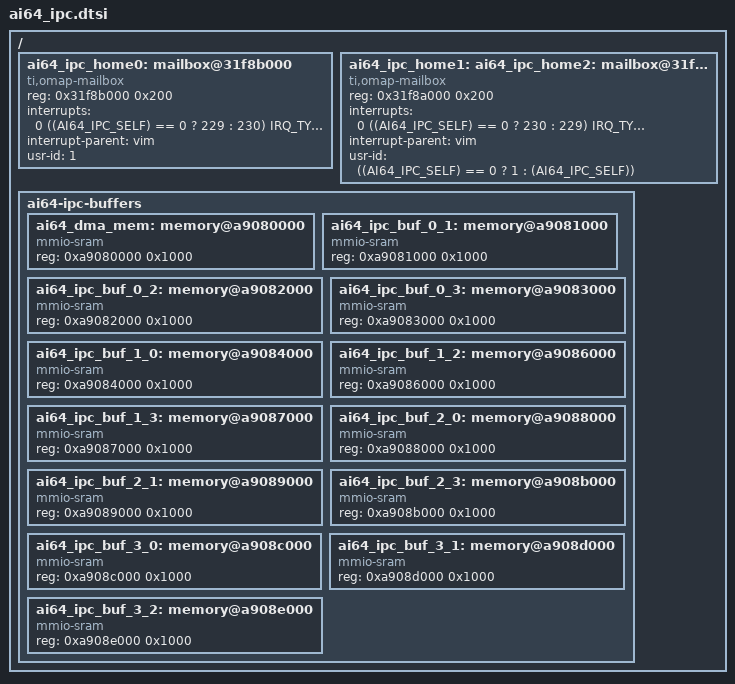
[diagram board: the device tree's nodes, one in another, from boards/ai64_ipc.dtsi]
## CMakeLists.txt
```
cmake_minimum_required(VERSION 3.20.0)

find_package(Zephyr REQUIRED HINTS $ENV{ZEPHYR_BASE})

project(ai64_r5 C CXX)

# EmbeddedRPC 1.14.0, cloned by build.sh. It is not used as a Zephyr module:
# that module's Kconfig selects SERIAL from a symbol that depends on the full
# C++ library, and the loop fails configuration. The library sources are
# compiled here, with erpc_malloc/erpc_free on the Zephyr heap. Transport is
# the existing OpenAMP RPMsg endpoint, not the module's UART or RPMsg-Lite
# ports.
set(ERPC ${CMAKE_CURRENT_LIST_DIR}/../../third_party/erpc/erpc_c)

# "r5f0_0" for board beaglebone_ai64/j721e/main_r5f0_0. The code names its
# core in logs with it, and in replies with AI64_CORE_NAME, "R5F0_0".
string(REGEX MATCH "r5f[0-9]_[0-9]" AI64_CORE "${BOARD_QUALIFIERS}")
if(NOT AI64_CORE)
  message(FATAL_ERROR "zephyr/r5 builds for a main-domain R5F core, not ${BOARD}${BOARD_QUALIFIERS}")
endif()
string(TOUPPER "${AI64_CORE}" AI64_CORE_NAME)
target_compile_definitions(app PRIVATE AI64_CORE="${AI64_CORE}" AI64_CORE_NAME="${AI64_CORE_NAME}")

# Its number among the four R5F cores (src/ai64_ipc.h), and its node on the
# fabric (zephyr/include/ai64_fabric.h), one more.
set(AI64_SELF_r5f0_0 0)
set(AI64_SELF_r5f0_1 1)
set(AI64_SELF_r5f1_0 2)
set(AI64_SELF_r5f1_1 3)
math(EXPR AI64_FAB_NODE "${AI64_SELF_${AI64_CORE}} + 1")
target_compile_definitions(app PRIVATE AI64_SELF=${AI64_SELF_${AI64_CORE}} AI64_FAB_NODE=${AI64_FAB_NODE})

target_include_directories(app PRIVATE
  ${CMAKE_CURRENT_SOURCE_DIR}/../include
  ${CMAKE_CURRENT_SOURCE_DIR}/../../dsp/include
  ${CMAKE_CURRENT_SOURCE_DIR}/../erpc/shim
  ${CMAKE_CURRENT_SOURCE_DIR}/src
  ${ERPC}/infra
  ${ERPC}/port
  ${ERPC}/setup
  ${LIBMETAL_INCLUDE_DIR}
  ${OPENAMP_INCLUDE_DIR}
  ${PLATFORM_DIR}
)

target_sources(app PRIVATE
  src/main.c
  src/ai64_service.c
  src/ai64_restart.c
  src/ai64_mpu.c
  src/ai64_tisci.c
  src/ai64_sproxy.c
  src/ai64_fabric.c
  src/ai64_ipc.c
  src/ai64_jobs.c
  src/ai64_erpc.cpp
  src/erpc_port_zephyr.cpp
  ../erpc/shim/c_ai64_server.cpp
  ../erpc/shim/ai64_server.cpp
  ../erpc/shim/ai64_interface.cpp
  ${ERPC}/infra/erpc_basic_codec.cpp
  ${ERPC}/infra/erpc_crc16.cpp
  ${ERPC}/infra/erpc_framed_transport.cpp
  ${ERPC}/infra/erpc_message_buffer.cpp
  ${ERPC}/infra/erpc_message_loggers.cpp
  ${ERPC}/infra/erpc_pre_post_action.cpp
  ${ERPC}/infra/erpc_server.cpp
  ${ERPC}/infra/erpc_simple_server.cpp
  ${ERPC}/infra/erpc_utils.cpp
  ${ERPC}/setup/erpc_server_setup.cpp
  ${ERPC}/setup/erpc_setup_mbf_dynamic.cpp
)

# This core's job (Kconfig, set in boards/<board>.conf).
target_sources_ifdef(CONFIG_AI64_JOB_SPI     app PRIVATE src/ai64_spi.c)
target_sources_ifdef(CONFIG_AI64_JOB_PWM     app PRIVATE src/ai64_pwm.c)
target_sources_ifdef(CONFIG_AI64_JOB_BLINK   app PRIVATE src/ai64_blink.c)
target_sources_ifdef(CONFIG_AI64_JOB_MONITOR app PRIVATE src/ai64_monitor.c)
target_sources_ifdef(CONFIG_AI64_DMA         app PRIVATE src/ai64_dma.c)
if(CONFIG_AI64_PIPE)
  target_sources_ifdef(CONFIG_AI64_JOB_SPI   app PRIVATE src/ai64_pipe_dma.c)
  target_sources_ifdef(CONFIG_AI64_JOB_PWM   app PRIVATE src/ai64_pipe_pwm.c)
endif()
```

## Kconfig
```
# SPDX-License-Identifier: MIT
#
# One app for the four main-domain R5F cores. sysbuild.cmake builds it once
# per core, and each core's boards/<board>.conf picks its job here. Every
# core also answers Linux over eRPC, sits on the fabric, and links to the
# other three over ipc_service (src/ai64_ipc.c).

menu "BeagleBone AI-64 demo"

choice AI64_JOB
	prompt "This core's job"

config AI64_JOB_SPI
	bool "SPI7 on header P9, and the UART2 console"
	help
	  R5F0_0. Writes SPI7 for Linux and for the other cores, and holds
	  the bulk buffer Linux writes.

config AI64_JOB_PWM
	bool "EHRPWM4 on P9.25"
	help
	  R5F0_1. Runs the step program on P9.25 and takes fixed settings
	  from Linux, the other cores, and fabric routes.

config AI64_JOB_BLINK
	bool "A square wave on P8.18 from a kernel timer"
	help
	  R5F1_0. Toggles GPIO0_4 from a k_timer and measures how late each
	  toggle is, on the GTC.

config AI64_JOB_MONITOR
	bool "Pings the other three cores and collects their status"
	help
	  R5F1_1. Measures each link's round trip and gathers every core's
	  job status for Linux.

endchoice

config AI64_DMA
	bool "A UDMA memory-to-memory channel (src/ai64_dma.c)"
	default y if AI64_JOB_SPI
	help
	  R5F0_0. Copies between DDR and the DSPs' memories for Linux's
	  dmaCopy call, with the main NAVSS UDMA.

config AI64_PIPE
	bool "This core's stage of the pipeline (zephyr/include/ai64_pipe.h)"
	default y if AI64_JOB_SPI || AI64_JOB_PWM
	select AI64_DMA if AI64_JOB_SPI
	help
	  R5F0_0 copies each window of P8.31 samples from ICSSG0 into C66x
	  0's L2 SRAM with its UDMA (src/ai64_pipe_dma.c). R5F0_1 sets P9.25
	  from the class the C7x finds for it, and keeps score
	  (src/ai64_pipe_pwm.c).

config AI64_BLINK_HALF_PERIOD_US
	int "Half period of the P8.18 square wave, in microseconds"
	depends on AI64_JOB_BLINK
	default 500

config AI64_MONITOR_PERIOD_MS
	int "How often the monitor pings every core, in milliseconds"
	depends on AI64_JOB_MONITOR
	default 100

endmenu

source "Kconfig.zephyr"
```

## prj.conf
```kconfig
CONFIG_IPM=y
CONFIG_MBOX=y
CONFIG_CPP=y
CONFIG_STD_CPP17=y
CONFIG_REQUIRES_FULL_LIBCPP=y
CONFIG_GLIBCXX_LIBCPP=y
CONFIG_MAIN_STACK_SIZE=2048
CONFIG_HEAP_MEM_POOL_SIZE=8192
CONFIG_SYSTEM_WORKQUEUE_STACK_SIZE=2048
CONFIG_OPENAMP=y
CONFIG_OPENAMP_RSC_TABLE=y
CONFIG_OPENAMP_MASTER=n
CONFIG_OPENAMP_RSC_TABLE_NUM_RPMSG_BUFF=8
CONFIG_LOG=y
CONFIG_LOG_DEFAULT_LEVEL=3
CONFIG_CACHE_MANAGEMENT=y
# TI-SCI over the polled secure proxy (src/ai64_sproxy.c), which starts at
# PRE_KERNEL_1 priority 5. Power domains, on R5F0_1 and R5F1_0, come after it.
CONFIG_TISCI_INIT_PRIORITY=10
# The links to the other R5F cores (src/ai64_ipc.c): ipc_service on the
# icmsg backend. A message is up to 180 bytes, more than pbuf's default
# read buffer.
CONFIG_IPC_SERVICE=y
CONFIG_PBUF_RX_READ_BUF_SIZE=256
```

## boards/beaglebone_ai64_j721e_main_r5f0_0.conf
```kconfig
# The ELF is build/zephyr-main_r5f0_0/zephyr/ai64_r5f0_0.elf. That is not the
# kernel's default name (j7-main-r5f0_0-fw), so the core stays off at boot
# until ai64-demo starts it.
CONFIG_KERNEL_BIN_NAME="ai64_r5f0_0"

# This core's job: SPI7 on header P9 (src/ai64_spi.c). It keeps the board's
# UART2 console.
CONFIG_AI64_JOB_SPI=y
CONFIG_SPI=y
```

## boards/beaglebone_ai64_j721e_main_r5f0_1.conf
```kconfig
# The ELF is build/zephyr-main_r5f0_1/zephyr/ai64_r5f0_1.elf. That is not the
# kernel's default name (j7-main-r5f0_1-fw), so the core stays off at boot
# until ai64-demo starts it.
CONFIG_KERNEL_BIN_NAME="ai64_r5f0_1"

# This core's job: EHRPWM4 on P9.25 (src/ai64_pwm.c). The device manager
# gives it its clock and power, over TI-SCI; the power domain turns it on at
# boot.
CONFIG_AI64_JOB_PWM=y
CONFIG_PWM=y
CONFIG_CLOCK_CONTROL=y
CONFIG_POWER_DOMAIN=y
CONFIG_POWER_DOMAIN_TISCI_INIT_PRIORITY=20

# This core has no console UART. Its log goes to a RAM buffer that the
# resource table lists as a trace, so Linux reads it at
# /sys/kernel/debug/remoteproc/remoteprocN/trace0.
CONFIG_CONSOLE=y
CONFIG_RAM_CONSOLE=y
CONFIG_LOG_MODE_MINIMAL=y
```

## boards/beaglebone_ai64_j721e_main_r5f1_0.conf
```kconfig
# The ELF is build/zephyr-main_r5f1_0/zephyr/ai64_r5f1_0.elf. That is not the
# kernel's default name (j7-main-r5f1_0-fw), so the core stays off at boot
# until ai64-demo starts it.
CONFIG_KERNEL_BIN_NAME="ai64_r5f1_0"

# This core's job: a square wave on P8.18 from GPIO2 (src/ai64_blink.c).
# The device manager powers GPIO2, over TI-SCI; the power domain turns it on
# at boot, before the GPIO driver starts.
CONFIG_AI64_JOB_BLINK=y
CONFIG_GPIO=y
CONFIG_POWER_DOMAIN=y
CONFIG_POWER_DOMAIN_TISCI_INIT_PRIORITY=20

# This core has no console UART. Its log goes to a RAM buffer that the
# resource table lists as a trace, so Linux reads it at
# /sys/kernel/debug/remoteproc/remoteprocN/trace0.
CONFIG_CONSOLE=y
CONFIG_RAM_CONSOLE=y
CONFIG_LOG_MODE_MINIMAL=y
```

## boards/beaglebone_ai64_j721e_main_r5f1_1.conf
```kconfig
# The ELF is build/zephyr-main_r5f1_1/zephyr/ai64_r5f1_1.elf. That is not the
# kernel's default name (j7-main-r5f1_1-fw), so the core stays off at boot
# until ai64-demo starts it.
CONFIG_KERNEL_BIN_NAME="ai64_r5f1_1"

# This core's job: ping the other three cores and collect their status
# (src/ai64_monitor.c).
CONFIG_AI64_JOB_MONITOR=y

# This core has no console UART. Its log goes to a RAM buffer that the
# resource table lists as a trace, so Linux reads it at
# /sys/kernel/debug/remoteproc/remoteprocN/trace0.
CONFIG_CONSOLE=y
CONFIG_RAM_CONSOLE=y
CONFIG_LOG_MODE_MINIMAL=y
```

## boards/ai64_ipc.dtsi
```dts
// SPDX-License-Identifier: MIT
/*
 * The R5F cores' links to each other: Zephyr ipc_service, icmsg backend.
 *
 * Every core has a link to every other, twelve one-way buffers in all. Core
 * n is R5F0_0, R5F0_1, R5F1_0, R5F1_1 for n = 0 to 3. The buffer from core
 * a to core b is 4 KiB at 0xa9080000 + (4a + b) * 4 KiB, inside the 1 MiB
 * the Linux overlay reserves for the fabric (which uses the first 128 KiB).
 *
 * Its doorbell is a FIFO of core b's home mailbox. Only two NAVSS mailbox
 * clusters have nobody listening after boot: 10 and 11 (the MCU R5F's
 * firmware, which runs the device manager, listens on cluster 7, and posts
 * to 5, 6, 8, and 9). Only users 1 to 3 of a cluster reach the interrupt
 * router. So cores 1 to 3 are users 1 to 3 of cluster 10, on FIFO 4a + b;
 * core 0 is user 1 of cluster 11, on FIFO 11 + a, since the fabric uses
 * that cluster's FIFOs 0 to 9 (ai64_fabric.h), without interrupts. Each core
 * asks the device manager to route its user's interrupt to its VIM input
 * 229 (src/ai64_tisci.c). A core sends on the other cluster too, but takes
 * no interrupt from it.
 *
 * A board overlay defines AI64_IPC_SELF, includes this file, and adds one
 * AI64_IPC_LINK(self, peer) for each of the other three cores.
 *
 * The slot for core 0 to itself carries no link: R5F0_0 keeps its DMA
 * rings and descriptor there (src/ai64_dma.c), non-cacheable like the rest.
 */

/*
 * unbound = "enable": a core that restarts opens its links with a new
 * session number, and the peer gets an unbound callback and opens the link
 * again (src/ai64_ipc.c). The buffers are non-cacheable on every core
 * (src/ai64_mpu.c); dcache-alignment keeps pbuf's indexes on their own
 * 32-byte lines anyway, which the session handshake needs.
 */
#define AI64_IPC_FIFO(a, b) ((b) == 0 ? 11 + (a) : (a) * 4 + (b))

#define AI64_IPC_LINK(self, peer)                                              \
	ai64_ipc_peer##peer: ipc_peer##peer {                                  \
		compatible = "zephyr,ipc-icmsg";                               \
		tx-region = <&ai64_ipc_buf_##self##_##peer>;                   \
		rx-region = <&ai64_ipc_buf_##peer##_##self>;                   \
		mboxes = <&ai64_ipc_home##peer AI64_IPC_FIFO(self, peer)>,     \
			 <&ai64_ipc_home##self AI64_IPC_FIFO(peer, self)>;     \
		mbox-names = "tx", "rx";                                       \
		unbound = "enable";                                            \
		dcache-alignment = <32>;                                       \
		status = "okay";                                               \
	};

/*
 * The cluster this core does not take interrupts from still needs one in
 * its node; VIM 230 is never routed or enabled.
 */
/ {
	ai64_ipc_home0: mailbox@31f8b000 {
		compatible = "ti,omap-mailbox";
		reg = <0x31f8b000 0x200>;
		interrupts = <0 ((AI64_IPC_SELF) == 0 ? 229 : 230) IRQ_TYPE_LEVEL
			      IRQ_DEFAULT_PRIORITY>;
		interrupt-parent = <&vim>;
		usr-id = <1>;
		#mbox-cells = <1>;
	};

	ai64_ipc_home1: ai64_ipc_home2: ai64_ipc_home3: mailbox@31f8a000 {
		compatible = "ti,omap-mailbox";
		reg = <0x31f8a000 0x200>;
		interrupts = <0 ((AI64_IPC_SELF) == 0 ? 230 : 229) IRQ_TYPE_LEVEL
			      IRQ_DEFAULT_PRIORITY>;
		interrupt-parent = <&vim>;
		usr-id = <((AI64_IPC_SELF) == 0 ? 1 : (AI64_IPC_SELF))>;
		#mbox-cells = <1>;
	};

	ai64-ipc-buffers {
		#address-cells = <1>;
		#size-cells = <1>;
		ranges;
		ai64_dma_mem: memory@a9080000 {
			compatible = "mmio-sram";
			reg = <0xa9080000 0x1000>;
		};
		ai64_ipc_buf_0_1: memory@a9081000 {
			compatible = "mmio-sram";
			reg = <0xa9081000 0x1000>;
		};
		ai64_ipc_buf_0_2: memory@a9082000 {
			compatible = "mmio-sram";
			reg = <0xa9082000 0x1000>;
		};
		ai64_ipc_buf_0_3: memory@a9083000 {
			compatible = "mmio-sram";
			reg = <0xa9083000 0x1000>;
		};
		ai64_ipc_buf_1_0: memory@a9084000 {
			compatible = "mmio-sram";
			reg = <0xa9084000 0x1000>;
		};
		ai64_ipc_buf_1_2: memory@a9086000 {
			compatible = "mmio-sram";
			reg = <0xa9086000 0x1000>;
		};
		ai64_ipc_buf_1_3: memory@a9087000 {
			compatible = "mmio-sram";
			reg = <0xa9087000 0x1000>;
		};
		ai64_ipc_buf_2_0: memory@a9088000 {
			compatible = "mmio-sram";
			reg = <0xa9088000 0x1000>;
		};
		ai64_ipc_buf_2_1: memory@a9089000 {
			compatible = "mmio-sram";
			reg = <0xa9089000 0x1000>;
		};
		ai64_ipc_buf_2_3: memory@a908b000 {
			compatible = "mmio-sram";
			reg = <0xa908b000 0x1000>;
		};
		ai64_ipc_buf_3_0: memory@a908c000 {
			compatible = "mmio-sram";
			reg = <0xa908c000 0x1000>;
		};
		ai64_ipc_buf_3_1: memory@a908d000 {
			compatible = "mmio-sram";
			reg = <0xa908d000 0x1000>;
		};
		ai64_ipc_buf_3_2: memory@a908e000 {
			compatible = "mmio-sram";
			reg = <0xa908e000 0x1000>;
		};
	};
};
```

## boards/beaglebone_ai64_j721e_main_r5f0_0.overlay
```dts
// SPDX-License-Identifier: MIT
#include <zephyr/dt-bindings/pinctrl/ti-k3-pinctrl.h>
#include <freq.h>
#include <zephyr/dt-bindings/interrupt-controller/ti-vim.h>

/*
 * Carve the bulk chunk region out of R5F0_0 DDR: 64 KiB at 0xa2fef000,
 * matching AI64_BULK_ADDR. ddr1 starts at 0xa2200000; the board's ddr1
 * (14 MiB) ended at 0xa3000000, and the last 4 KiB stay unused.
 */

&ddr1 {
	reg = <0xa2200000 0xdef000>;
};

/*
 * 0x200000 is the pad's TX-disable bit (PIN_DISABLE in the Linux header),
 * OR mux mode 7, so a shorted partner ball stays off. The K3 pinctrl helper
 * applies only the first two pinmux cells of each group, so each group has
 * one pin.
 */
#define AI64_PIN_OFF 0x200000

/ {
	ai64_bulk: memory@a2fef000 {
		compatible = "zephyr,memory-region", "mmio-sram";
		reg = <0xa2fef000 0x10000>;
		zephyr,memory-region = "AI64_BULK";
	};

	/*
	 * Main SPI7. Linux leaves it disabled, and the board firmware keeps
	 * its power domain on. The driver polls, so there is no interrupt.
	 * Its functional clock is 50 MHz: with 48 here, the driver's divider
	 * of 48 for 1 MHz gave a 0.96 us clock on a logic analyzer.
	 */
	main_spi7: spi@2170000 {
		compatible = "ti,omap-mcspi";
		reg = <0x02170000 0x400>;
		clock-frequency = <DT_FREQ_M(50)>;
		ti,spi-num-cs = <1>;
		ti,d1-miso-d0-mosi;
		#address-cells = <1>;
		#size-cells = <0>;
		pinctrl-names = "default";
		pinctrl-0 = <&ai64_spi7_clk &ai64_spi7_cs0 &ai64_spi7_d0
			     &ai64_spi7_off_p9_31b &ai64_spi7_off_p9_28b
			     &ai64_spi7_off_p9_30b>;
		status = "okay";
	};
};

&pinctrl {
	ai64_spi7_clk: ai64-spi7-clk {
		/* P9.31a U3 EXT_REFCLK1.SPI7_CLK, mode 6 */
		pinmux = <K3_PINMUX(0x0234, PIN_OUTPUT, MUX_MODE_6)>;
	};
	ai64_spi7_cs0: ai64-spi7-cs0 {
		/* P9.28a U2 ECAP0_IN_APWM_OUT.SPI7_CS0, mode 6 */
		pinmux = <K3_PINMUX(0x0230, PIN_OUTPUT, MUX_MODE_6)>;
	};
	ai64_spi7_d0: ai64-spi7-d0 {
		/* P9.30a V6 TIMER_IO0.SPI7_D0, MOSI, mode 6 */
		pinmux = <K3_PINMUX(0x0238, PIN_OUTPUT, MUX_MODE_6)>;
	};
	ai64_spi7_off_p9_31b: ai64-spi7-off-p9-31b {
		/* P9.31b AB26, shorted to P9.31a */
		pinmux = <K3_PINMUX(0x00d4, AI64_PIN_OFF, MUX_MODE_7)>;
	};
	ai64_spi7_off_p9_28b: ai64-spi7-off-p9-28b {
		/* P9.28b AF28, shorted to P9.28a */
		pinmux = <K3_PINMUX(0x00b0, AI64_PIN_OFF, MUX_MODE_7)>;
	};
	ai64_spi7_off_p9_30b: ai64-spi7-off-p9-30b {
		/* P9.30b AE28, shorted to P9.30a */
		pinmux = <K3_PINMUX(0x00b4, AI64_PIN_OFF, MUX_MODE_7)>;
	};
};

/*
 * TI-SCI, the device manager's API. Zephyr's TI-SCI driver talks to it over
 * this host's (35) threads on main_sec_proxy0: 63 (low_priority,
 * write) and 61 (response, read; k3conf show threads). The polled mailbox
 * driver in src/ai64_sproxy.c carries it, since no secure proxy interrupt
 * reaches an R5F here. reg is the device manager's debug window, which the
 * binding asks for and nothing reads.
 */
/ {
	ai64_sproxy: mailbox@32c00000 {
		compatible = "ai64,secure-proxy-poll";
		reg = <0x32c00000 0x100000>, <0x32400000 0x100000>;
		reg-names = "target_data", "rt";
		#mbox-cells = <1>;
	};

	dmsc: system-controller@44083000 {
		compatible = "ti,k2g-sci";
		reg = <0x44083000 0x1000>;
		ti,host-id = <35>;
		mboxes = <&ai64_sproxy 61>, <&ai64_sproxy 63>;
		mbox-names = "rx", "tx";
	};
};

/*
 * The mailbox interrupt route this core asks the device manager for at boot
 * (src/ai64_tisci.c), through Zephyr's TI-SCI driver.
 * NAVSS0_MAILBOX_1 user 2 arrives on NAVSS0_INTR_ROUTER_0
 * (device 213) input 434. Output 196 is the first of this host's range
 * (k3conf dump rm 213) and lands on this core's VIM input 228.
 */
/ {
	ai64_tisci: tisci-route {
		compatible = "ai64,tisci-irq-route";
		ir-id = <213>;
		ir-input = <434>;
		ir-output = <196>;
	};
};

/* The board puts the mailbox on VIM 256, which nothing routes to. */
&mbox1 {
	interrupts = <0 228 IRQ_TYPE_LEVEL IRQ_DEFAULT_PRIORITY>;
};

/*
 * The links to the other three R5F cores (boards/ai64_ipc.dtsi). This core's
 * doorbells are NAVSS0_MAILBOX_11 user 1, which arrives on router input 393
 * (TI-SCI's pend_intr 0); output 197, the next of this host's range, lands
 * on VIM input 229.
 */
#define AI64_IPC_SELF 0
#include "ai64_ipc.dtsi"

/ {
	ai64_tisci_ipc: tisci-route-ipc {
		compatible = "ai64,tisci-irq-route";
		ir-id = <213>;
		ir-input = <393>;
		ir-output = <197>;
	};

	AI64_IPC_LINK(0, 1)
	AI64_IPC_LINK(0, 2)
	AI64_IPC_LINK(0, 3)
};
```

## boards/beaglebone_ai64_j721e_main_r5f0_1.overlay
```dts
// SPDX-License-Identifier: MIT
#include <zephyr/dt-bindings/pinctrl/ti-k3-pinctrl.h>
#include <zephyr/dt-bindings/interrupt-controller/ti-vim.h>
#include <zephyr/dt-bindings/pwm/pwm.h>

/*
 * R5F0_1's job: EHRPWM4 output B on P9.25 (src/ai64_pwm.c).
 *
 * 0x200000 is the pad's TX-disable bit (PIN_DISABLE in the Linux header),
 * OR mux mode 7, so the shorted partner ball stays off. The K3 pinctrl
 * helper applies only the first two pinmux cells of each group, so each
 * group has one pin.
 */
#define AI64_PIN_OFF 0x200000

&pinctrl {
	ai64_epwm4_b: ai64-epwm4-b {
		/* P9.25b W26 RGMII6_RXC.EHRPWM4_B, mode 6 */
		pinmux = <K3_PINMUX(0x01a4, PIN_OUTPUT, MUX_MODE_6)>;
	};
	ai64_epwm4_off_p9_25a: ai64-epwm4-off-p9-25a {
		/* P9.25a AC4, shorted to P9.25b */
		pinmux = <K3_PINMUX(0x0200, AI64_PIN_OFF, MUX_MODE_7)>;
	};
};

/*
 * Zephyr's EHRPWM driver (ti,am3352-ehrpwm). Its functional clock and power
 * come from the device manager over TI-SCI (dmsc, below): device 87, clock
 * 0, as in the Linux device tree's main_ehrpwm4. The power domain turns the
 * module on at boot. The time-base clock gate is CTRLMMR_EPWM4_CTRL bit 0,
 * at 0x4150 in CTRL_MMR0 (Linux's ehrpwm_tbclk 4), in the partition that
 * kicks at 0x5008. Linux leaves EHRPWM4 alone once install-beagle.sh has
 * taken the stock image's epwm4 overlay out of its boot entry.
 * src/ai64_pwm.c drives it, through the pwms of /zephyr,user.
 */
/ {
	main_ctrl_mmr0: syscon@100000 {
		compatible = "ti,control-module", "syscon";
		reg = <0x00100000 0x1c000>;
		ti,unlock-offsets = <0x5008>;
		#epwm-tbclk-cells = <2>;
	};

	power-domains {
		epwm4_pd: epwm4-pd {
			compatible = "ti,sci-pm-domain";
			tisci,device-id = <87>;
			tisci,device-mode = "EXCLUSIVE";
			#power-domain-cells = <0>;
		};
	};

	main_ehrpwm4: pwm@3040000 {
		compatible = "ti,am3352-ehrpwm";
		reg = <0x03040000 0x100>;
		clocks = <&k3_clks 87 0>;
		tbclk = <&main_ctrl_mmr0 0x4150 0>;
		power-domains = <&epwm4_pd>;
		pinctrl-0 = <&ai64_epwm4_b &ai64_epwm4_off_p9_25a>;
		pinctrl-names = "default";
		#pwm-cells = <3>;
	};

	zephyr,user {
		/* Output B is channel 1. 1 kHz until the steps start. */
		pwms = <&main_ehrpwm4 1 PWM_MSEC(1) PWM_POLARITY_NORMAL>;
	};
};

/*
 * TI-SCI, the device manager's API. Zephyr's TI-SCI driver talks to it over
 * this host's (37) threads on main_sec_proxy0: 73 (low_priority,
 * write) and 71 (response, read; k3conf show threads). The polled mailbox
 * driver in src/ai64_sproxy.c carries it, since no secure proxy interrupt
 * reaches an R5F here. reg is the device manager's debug window, which the
 * binding asks for and nothing reads.
 */
/ {
	ai64_sproxy: mailbox@32c00000 {
		compatible = "ai64,secure-proxy-poll";
		reg = <0x32c00000 0x100000>, <0x32400000 0x100000>;
		reg-names = "target_data", "rt";
		#mbox-cells = <1>;
	};

	dmsc: system-controller@44083000 {
		compatible = "ti,k2g-sci";
		reg = <0x44083000 0x1000>;
		ti,host-id = <37>;
		mboxes = <&ai64_sproxy 71>, <&ai64_sproxy 73>;
		mbox-names = "rx", "tx";

		k3_clks: clock-controller {
			compatible = "ti,k2g-sci-clk";
			#clock-cells = <2>;
		};
	};
};

/*
 * The mailbox interrupt routes this core asks the device manager for at
 * boot (src/ai64_tisci.c), through Zephyr's TI-SCI driver, both on
 * NAVSS0_INTR_ROUTER_0 (device 213), whose outputs 228 to 255 are this
 * host's (k3conf dump rm 213) and land on this core's VIM inputs 228 to 255:
 * - Linux's doorbell, NAVSS0_MAILBOX_1 user 1: router input 433, output 228,
 *   VIM 228.
 * - The other R5F cores' doorbells, NAVSS0_MAILBOX_10 user 1
 *   (boards/ai64_ipc.dtsi): router input 397 (TI-SCI's pend_intr 0),
 *   output 229, VIM 229.
 */
/ {
	ai64_tisci: tisci-route {
		compatible = "ai64,tisci-irq-route";
		ir-id = <213>;
		ir-input = <433>;
		ir-output = <228>;
	};

	ai64_tisci_ipc: tisci-route-ipc {
		compatible = "ai64,tisci-irq-route";
		ir-id = <213>;
		ir-input = <397>;
		ir-output = <229>;
	};
};

/* The board puts the mailbox on VIM 256, which nothing routes to. */
&mbox1 {
	interrupts = <0 228 IRQ_TYPE_LEVEL IRQ_DEFAULT_PRIORITY>;
};

#define AI64_IPC_SELF 1
#include "ai64_ipc.dtsi"

/ {
	AI64_IPC_LINK(1, 0)
	AI64_IPC_LINK(1, 2)
	AI64_IPC_LINK(1, 3)
};
```

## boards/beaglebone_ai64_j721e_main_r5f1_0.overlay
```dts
// SPDX-License-Identifier: MIT
#include <zephyr/dt-bindings/interrupt-controller/ti-vim.h>

/*
 * TI-SCI, the device manager's API. Zephyr's TI-SCI driver talks to it over
 * this host's (40) threads on main_sec_proxy0: 83 (low_priority,
 * write) and 81 (response, read; k3conf show threads). The polled mailbox
 * driver in src/ai64_sproxy.c carries it, since no secure proxy interrupt
 * reaches an R5F here. reg is the device manager's debug window, which the
 * binding asks for and nothing reads.
 */
/ {
	ai64_sproxy: mailbox@32c00000 {
		compatible = "ai64,secure-proxy-poll";
		reg = <0x32c00000 0x100000>, <0x32400000 0x100000>;
		reg-names = "target_data", "rt";
		#mbox-cells = <1>;
	};

	dmsc: system-controller@44083000 {
		compatible = "ti,k2g-sci";
		reg = <0x44083000 0x1000>;
		ti,host-id = <40>;
		mboxes = <&ai64_sproxy 81>, <&ai64_sproxy 83>;
		mbox-names = "rx", "tx";
	};
};

/*
 * The mailbox interrupt route this core asks the device manager for at boot
 * (src/ai64_tisci.c), through Zephyr's TI-SCI driver.
 * NAVSS0_MAILBOX_2 user 1 arrives on NAVSS0_INTR_ROUTER_0
 * (device 213) input 429. Output 260 is the first of this host's range
 * (k3conf dump rm 213) and lands on this core's VIM input 228.
 */
/ {
	ai64_tisci: tisci-route {
		compatible = "ai64,tisci-irq-route";
		ir-id = <213>;
		ir-input = <429>;
		ir-output = <260>;
	};
};

/* The board puts the mailbox on VIM 256, which nothing routes to. */
&mbox2 {
	interrupts = <0 228 IRQ_TYPE_LEVEL IRQ_DEFAULT_PRIORITY>;
};

/*
 * The links to the other three R5F cores (boards/ai64_ipc.dtsi). This core's
 * doorbells are NAVSS0_MAILBOX_10 user 2, which arrives on router input
 * 398 (TI-SCI's pend_intr 1); output 261, the next of this host's range,
 * lands on VIM input 229.
 */
#define AI64_IPC_SELF 2
#include "ai64_ipc.dtsi"

/ {
	ai64_tisci_ipc: tisci-route-ipc {
		compatible = "ai64,tisci-irq-route";
		ir-id = <213>;
		ir-input = <398>;
		ir-output = <261>;
	};

	AI64_IPC_LINK(2, 0)
	AI64_IPC_LINK(2, 1)
	AI64_IPC_LINK(2, 3)
};

/*
 * R5F1_0's job: a square wave on P8.18 (src/ai64_blink.c).
 *
 * The pad, AJ23 at 0x010, is GPIO0_4 in mux mode 7. Bits 5:4 of a J721E
 * pad register pick which of the main domain's GPIO0, GPIO2, GPIO4, and
 * GPIO6 drives it (1 is GPIO2). Linux owns GPIO0, and has outputs in every
 * one of its banks, but leaves GPIO2 disabled, so this core takes GPIO2
 * whole: Zephyr's GPIO driver sets every pin of a bank to input when it
 * starts. GPIO2's power and clock come from the device manager (device
 * 107), which the power domain turns on at boot.
 */
#include <zephyr/dt-bindings/pinctrl/ti-k3-pinctrl.h>
#include <zephyr/dt-bindings/gpio/gpio.h>

#define AI64_GPIO2_SEL (1 << 4)

&pinctrl {
	ai64_blink_p8_18: ai64-blink-p8-18 {
		/* P8.18 AJ23 GPIO0_4, here GPIO2_4, mode 7 */
		pinmux = <K3_PINMUX(0x0010, PIN_OUTPUT | AI64_GPIO2_SEL, MUX_MODE_7)>;
	};
};

/ {
	power-domains {
		gpio2_pd: gpio2-pd {
			compatible = "ti,sci-pm-domain";
			tisci,device-id = <107>;
			tisci,device-mode = "EXCLUSIVE";
			#power-domain-cells = <0>;
		};
	};

	zephyr,user {
		blink-gpios = <&main_gpio2 4 GPIO_ACTIVE_HIGH>;
	};
};

/* GPIO2's first bank, pins 0 to 31 (main_gpio2 maps pin n to it). */
&main_gpio2_0 {
	power-domains = <&gpio2_pd>;
	pinctrl-0 = <&ai64_blink_p8_18>;
	pinctrl-names = "default";
	status = "okay";
};
```

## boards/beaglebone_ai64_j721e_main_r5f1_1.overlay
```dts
// SPDX-License-Identifier: MIT
#include <zephyr/dt-bindings/interrupt-controller/ti-vim.h>

/*
 * TI-SCI, the device manager's API. Zephyr's TI-SCI driver talks to it over
 * this host's (42) threads on main_sec_proxy0: 93 (low_priority,
 * write) and 91 (response, read; k3conf show threads). The polled mailbox
 * driver in src/ai64_sproxy.c carries it, since no secure proxy interrupt
 * reaches an R5F here. reg is the device manager's debug window, which the
 * binding asks for and nothing reads.
 */
/ {
	ai64_sproxy: mailbox@32c00000 {
		compatible = "ai64,secure-proxy-poll";
		reg = <0x32c00000 0x100000>, <0x32400000 0x100000>;
		reg-names = "target_data", "rt";
		#mbox-cells = <1>;
	};

	dmsc: system-controller@44083000 {
		compatible = "ti,k2g-sci";
		reg = <0x44083000 0x1000>;
		ti,host-id = <42>;
		mboxes = <&ai64_sproxy 91>, <&ai64_sproxy 93>;
		mbox-names = "rx", "tx";
	};
};

/*
 * The mailbox interrupt route this core asks the device manager for at boot
 * (src/ai64_tisci.c), through Zephyr's TI-SCI driver.
 * NAVSS0_MAILBOX_2 user 2 arrives on NAVSS0_INTR_ROUTER_0
 * (device 213) input 430. Output 292 is the first of this host's range
 * (k3conf dump rm 213) and lands on this core's VIM input 228.
 */
/ {
	ai64_tisci: tisci-route {
		compatible = "ai64,tisci-irq-route";
		ir-id = <213>;
		ir-input = <430>;
		ir-output = <292>;
	};
};

/* The board puts the mailbox on VIM 256, which nothing routes to. */
&mbox2 {
	interrupts = <0 228 IRQ_TYPE_LEVEL IRQ_DEFAULT_PRIORITY>;
};

/*
 * The links to the other three R5F cores (boards/ai64_ipc.dtsi). This core's
 * doorbells are NAVSS0_MAILBOX_10 user 3, which arrives on router input
 * 399 (TI-SCI's pend_intr 2); output 293, the next of this host's range,
 * lands on VIM input 229.
 */
#define AI64_IPC_SELF 3
#include "ai64_ipc.dtsi"

/ {
	ai64_tisci_ipc: tisci-route-ipc {
		compatible = "ai64,tisci-irq-route";
		ir-id = <213>;
		ir-input = <399>;
		ir-output = <293>;
	};

	AI64_IPC_LINK(3, 0)
	AI64_IPC_LINK(3, 1)
	AI64_IPC_LINK(3, 2)
};
```

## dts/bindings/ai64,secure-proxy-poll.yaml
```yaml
# SPDX-License-Identifier: MIT
description: |
  The main secure proxy, as a mailbox with no interrupt: a send waits for
  the answer on the enabled receive threads (src/ai64_sproxy.c). It carries
  Zephyr's TI-SCI driver (ti,k2g-sci) on the main-domain R5Fs, where no
  secure proxy interrupt is routed. A channel is a secure proxy thread.

compatible: "ai64,secure-proxy-poll"

include: [base.yaml, mailbox-controller.yaml]

properties:
  reg:
    required: true

  reg-names:
    required: true
    description: '"target_data" and "rt"'

mbox-cells:
  - channel
```

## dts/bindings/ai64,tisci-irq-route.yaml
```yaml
# SPDX-License-Identifier: MIT
description: |
  One NAVSS interrupt-router route this R5F core asks the device manager to
  set up at boot (TI-SCI RM_IRQ_SET), through the dmsc node.
  src/ai64_tisci.c reads it.

  The route is router input -> router output, the way Linux's ti,sci-intr
  and Zephyr PR #121379 program it: src and dst are both the router. The
  output must be in this host's range (k3conf dump rm 213), and the TI-SCI
  J721E interrupt tables say which VIM input that output lands on.

compatible: "ai64,tisci-irq-route"

properties:
  ir-id:
    type: int
    required: true
    description: TI-SCI device ID of the interrupt router (NAVSS0_INTR_ROUTER_0 is 213)

  ir-input:
    type: int
    required: true
    description: router input the mailbox user interrupt arrives on

  ir-output:
    type: int
    required: true
    description: router output to connect it to
```

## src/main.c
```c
/* SPDX-License-Identifier: MIT */
/*
 * Zephyr on a BeagleBone AI-64 main-domain R5F core: its link to Linux.
 *
 * Linux calls Zephyr functions over eRPC on RPMsg (channel "rpmsg-raw",
 * address 1024), on every core (ai64_service.c). Each core's job runs from
 * its own file: ai64_spi.c, ai64_pwm.c, ai64_blink.c, or ai64_monitor.c.
 */

#include <zephyr/kernel.h>
#include <zephyr/device.h>
#include <zephyr/drivers/ipm.h>
#include <zephyr/sys/printk.h>
#include <zephyr/sys/barrier.h>
#include <zephyr/cache.h>
#include <zephyr/sys/sys_io.h>
#include <zephyr/irq.h>
#include <zephyr/logging/log.h>

#include <errno.h>

#include <openamp/open_amp.h>
#include <metal/sys.h>
#include <metal/io.h>
#include <resource_table.h>
#include <addr_translation.h>

#include "ai64_shm.h"
#include "ai64_erpc.h"
#include "ai64_tisci.h"
#if CONFIG_AI64_DMA
#include "ai64_dma.h"
#endif

LOG_MODULE_REGISTER(ai64_r5, LOG_LEVEL_INF);

#define RPMSG_CHAN_NAME "rpmsg-raw"
#define RPMSG_CHAN_ADDR 1024

#if CONFIG_IPM_MAX_DATA_SIZE > 0
#define IPM_SEND(dev, w, id, d, s) ipm_send(dev, w, id, d, s)
#else
#define IPM_SEND(dev, w, id, d, s) ipm_send(dev, w, id, NULL, 0)
#endif

#define SHM_NODE       DT_CHOSEN(zephyr_ipc_shm)
#define SHM_START_ADDR DT_REG_ADDR(SHM_NODE)
#define SHM_SIZE       DT_REG_SIZE(SHM_NODE)

#if !DT_HAS_CHOSEN(zephyr_ipc_shm)
#error "R5F board must choose zephyr,ipc_shm"
#endif

static const struct device *const ipm_handle = DEVICE_DT_GET(DT_CHOSEN(zephyr_ipc));

static metal_phys_addr_t shm_physmap = SHM_START_ADDR;
static metal_phys_addr_t rsc_tab_physmap;
static struct metal_io_region shm_io_data;
static struct metal_io_region rsc_io_data;
static struct metal_io_region *shm_io = &shm_io_data;
static struct metal_io_region *rsc_io = &rsc_io_data;
static struct rpmsg_virtio_device rvdev;
static struct rpmsg_device *rpdev;
static struct rpmsg_endpoint ept;
static void *rsc_table;

static K_SEM_DEFINE(mb_sem, 0, 1);

/*
 * Linux kicks this core through a mailbox FIFO. On J721E that mailbox
 * interrupt only reaches the R5F's VIM once the device manager routes it
 * through the NAVSS interrupt router, which ai64_route_mbox_irq() asks for
 * at boot. If that fails, the RPMsg thread polls the FIFO once a
 * millisecond instead and pops what it finds.
 */
#define IPC_NODE      DT_CHOSEN(zephyr_ipc)
#define MBOX_NODE     DT_PHANDLE_BY_NAME(IPC_NODE, mboxes, rx)
#define MBOX_BASE     DT_REG_ADDR(MBOX_NODE)
#define MBOX_RX_FIFO  DT_PHA_BY_NAME(IPC_NODE, mboxes, rx, channel)
#define MBOX_TX_FIFO  DT_PHA_BY_NAME(IPC_NODE, mboxes, tx, channel)
#define MBOX_MESSAGE(m)   (MBOX_BASE + 0x40u + 4u * (m))
#define MBOX_MSGSTATUS(m) (MBOX_BASE + 0xc0u + 4u * (m))

/*
 * TI's 6.18 kernel (the Yocto image) stops an R5F by sending RP_MBOX_SHUTDOWN
 * and waiting for the ACK and for the core to sit in WFI. The BeagleBoard
 * 6.18 Debian kernel sends nothing and just halts the core.
 */
#define RP_MBOX_SHUTDOWN     0xFFFFFF14u
#define RP_MBOX_SHUTDOWN_ACK 0xFFFFFF15u

static bool mbox_irq_routed;
static atomic_t shutdown_requested;

static FUNC_NORETURN void park_for_shutdown(void)
{
	unsigned int i;

#if CONFIG_AI64_DMA
	/* A DMA channel left on would still be on when the core runs again. */
	ai64_dma_stop();
#endif
	sys_write32(RP_MBOX_SHUTDOWN_ACK, MBOX_MESSAGE(MBOX_TX_FIFO));
	(void)arch_irq_lock();
	/* A pending interrupt, even a masked one, wakes WFI. Mask them at the VIM. */
	for (i = 0; i < CONFIG_NUM_IRQS; i++) {
		irq_disable(i);
	}
	for (;;) {
		__asm__ volatile("dsb; wfi" ::: "memory");
	}
}

/* Pop every queued kick. Returns how many there were. */
static uint32_t mbox_rx_drain(void)
{
	uint32_t n = 0;

	while (sys_read32(MBOX_MSGSTATUS(MBOX_RX_FIFO)) & 0x3fu) {
		if (sys_read32(MBOX_MESSAGE(MBOX_RX_FIFO)) == RP_MBOX_SHUTDOWN) {
			LOG_INF("shutdown request from Linux");
			park_for_shutdown();
		}
		n++;
	}
	return n;
}

static void platform_ipm_callback(const struct device *dev, void *context,
				  uint32_t id, volatile void *data)
{
	ARG_UNUSED(dev);
	ARG_UNUSED(context);
	ARG_UNUSED(id);

	/* The mailbox driver hands over the message it popped. */
	if (data && *(volatile uint32_t *)data == RP_MBOX_SHUTDOWN) {
		atomic_set(&shutdown_requested, 1);
	}
	k_sem_give(&mb_sem);
}

static int mailbox_notify(void *priv, uint32_t id)
{
	ARG_UNUSED(priv);
	IPM_SEND(ipm_handle, 0, id, &id, 4);
	return 0;
}

static int platform_init(void)
{
	struct metal_init_params metal_params = METAL_INIT_DEFAULTS;
	int rsc_size;
	int status;

	status = metal_init(&metal_params);
	if (status) {
		LOG_ERR("metal_init failed: %d", status);
		return -1;
	}

	metal_io_init(shm_io, (void *)SHM_START_ADDR, &shm_physmap, SHM_SIZE,
		      -1, 0, addr_translation_get_ops(shm_physmap));

	rsc_table_get(&rsc_table, &rsc_size);
	rsc_tab_physmap = (uintptr_t)rsc_table;
	metal_io_init(rsc_io, rsc_table, &rsc_tab_physmap, rsc_size, -1, 0, NULL);

	mbox_irq_routed = ai64_route_mbox_irq() == 0;

	if (!device_is_ready(ipm_handle)) {
		LOG_ERR("IPM device is not ready");
		return -1;
	}
	ipm_register_callback(ipm_handle, platform_ipm_callback, NULL);
	status = ipm_set_enabled(ipm_handle, 1);
	if (status) {
		LOG_ERR("ipm_set_enabled failed");
		return -1;
	}
	return 0;
}

static struct rpmsg_device *platform_create_rpmsg_vdev(void)
{
	struct fw_rsc_vdev_vring *vring_rsc;
	struct virtio_device *vdev;
	int ret;

	vdev = rproc_virtio_create_vdev(VIRTIO_DEV_DEVICE, VDEV_ID,
					rsc_table_to_vdev(rsc_table),
					rsc_io, NULL, mailbox_notify, NULL);
	if (!vdev) {
		LOG_ERR("failed to create vdev");
		return NULL;
	}

	rproc_virtio_wait_remote_ready(vdev);

	vring_rsc = rsc_table_get_vring0(rsc_table);
	ret = rproc_virtio_init_vring(vdev, 0, vring_rsc->notifyid,
				      (void *)vring_rsc->da, rsc_io,
				      vring_rsc->num, vring_rsc->align);
	if (ret) {
		LOG_ERR("failed to init vring 0");
		goto failed;
	}

	vring_rsc = rsc_table_get_vring1(rsc_table);
	ret = rproc_virtio_init_vring(vdev, 1, vring_rsc->notifyid,
				      (void *)vring_rsc->da, rsc_io,
				      vring_rsc->num, vring_rsc->align);
	if (ret) {
		LOG_ERR("failed to init vring 1");
		goto failed;
	}

	ret = rpmsg_init_vdev(&rvdev, vdev, NULL, shm_io, NULL);
	if (ret) {
		LOG_ERR("failed rpmsg_init_vdev");
		goto failed;
	}
	return rpmsg_virtio_get_rpmsg_device(&rvdev);

failed:
	rproc_virtio_remove_vdev(vdev);
	return NULL;
}

static int rx_cb(struct rpmsg_endpoint *ept_dev, void *data, size_t len,
		 uint32_t src, void *priv)
{
	ARG_UNUSED(ept_dev);
	ARG_UNUSED(src);
	ARG_UNUSED(priv);

	ai64_erpc_push(data, len);
	return RPMSG_SUCCESS;
}

int ai64_rpmsg_tx(const void *data, size_t len)
{
	int ret = rpmsg_send(&ept, (void *)data, len);

	return ret < 0 ? -1 : 0;
}

static void app_thread(void *a, void *b, void *c)
{
	ARG_UNUSED(a);
	ARG_UNUSED(b);
	ARG_UNUSED(c);

	ai64_erpc_server();
}

static void rpmsg_thread(void *a, void *b, void *c)
{
	ARG_UNUSED(a);
	ARG_UNUSED(b);
	ARG_UNUSED(c);

	if (platform_init()) {
		return;
	}
	rpdev = platform_create_rpmsg_vdev();
	if (!rpdev) {
		return;
	}

	if (rpmsg_create_ept(&ept, rpdev, RPMSG_CHAN_NAME, RPMSG_CHAN_ADDR,
			     RPMSG_ADDR_ANY, rx_cb, NULL)) {
		LOG_ERR("rpmsg_create_ept failed");
		return;
	}
	LOG_INF("rpmsg channel %s addr %d is up", RPMSG_CHAN_NAME, RPMSG_CHAN_ADDR);

	while (1) {
		int woke = k_sem_take(&mb_sem, mbox_irq_routed ? K_FOREVER : K_MSEC(1)) == 0;

		if (atomic_get(&shutdown_requested)) {
			LOG_INF("shutdown request from Linux");
			park_for_shutdown();
		}
		if (mbox_rx_drain() || woke) {
			rproc_virtio_notified(rvdev.vdev, VRING1_ID);
		}
	}
}

K_THREAD_DEFINE(rpmsg_tid, 4096, rpmsg_thread, NULL, NULL, NULL, K_PRIO_COOP(8), 0, 0);
K_THREAD_DEFINE(app_tid, 8192, app_thread, NULL, NULL, NULL, K_PRIO_COOP(7), 0, 0);

int main(void)
{
	LOG_INF("ai64 " AI64_CORE " hello");
	return 0;
}
```

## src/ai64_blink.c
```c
/* SPDX-License-Identifier: MIT */
/*
 * R5F1_0's job: a square wave on P8.18, Zephyr's blinky with a logic
 * analyzer in mind.
 *
 * A periodic k_timer toggles GPIO2_4 (the overlay muxes it to P8.18) every
 * CONFIG_AI64_BLINK_HALF_PERIOD_US, from the timer's interrupt, through
 * Zephyr's GPIO driver: 1 kHz with the default 500 us. Each toggle reads the
 * GTC, so the core measures its own timing: how far each half period is
 * from the one asked for. Every 1000 toggles it keeps the smallest, the
 * largest, and the mean of those, for the status line.
 */

#include <zephyr/kernel.h>
#include <zephyr/drivers/gpio.h>
#include <zephyr/sys/sys_io.h>
#include <zephyr/logging/log.h>
#include <stdio.h>

#include "ai64_ipc.h"
#include "ai64_shm.h"

LOG_MODULE_DECLARE(ai64_r5, LOG_LEVEL_INF);

#define HALF_US      CONFIG_AI64_BLINK_HALF_PERIOD_US
#define HALF_GTC     ((int32_t)(HALF_US * (AI64_GTC_HZ / 1000000u)))
#define WINDOW       1000u
#define GTC_NS(t)    ((int32_t)(t) * (int32_t)(1000000000u / AI64_GTC_HZ))

static const struct gpio_dt_spec pin = GPIO_DT_SPEC_GET(DT_PATH(zephyr_user), blink_gpios);

struct window {
	int32_t min, max;
	int64_t sum;
	uint32_t n;
};

static struct window cur, last;
static uint32_t toggles, prev;
static int32_t worst;
static struct k_spinlock lock;

static void blink(struct k_timer *t)
{
	uint32_t now = sys_read32(AI64_GTC_ADDR + 8u);
	int32_t err;
	k_spinlock_key_t key;

	ARG_UNUSED(t);
	(void)gpio_pin_toggle_dt(&pin);
	key = k_spin_lock(&lock);
	if (toggles++ != 0u) {
		err = (int32_t)(now - prev) - HALF_GTC;
		if (cur.n == 0u || err < cur.min) {
			cur.min = err;
		}
		if (cur.n == 0u || err > cur.max) {
			cur.max = err;
		}
		if ((err < 0 ? -err : err) > worst) {
			worst = err < 0 ? -err : err;
		}
		cur.sum += err;
		if (++cur.n == WINDOW) {
			last = cur;
			cur = (struct window){0};
		}
	}
	prev = now;
	k_spin_unlock(&lock, key);
}

static K_TIMER_DEFINE(timer, blink, NULL);

void ai64_job_status(char *buf, size_t len)
{
	struct window w;
	uint32_t n;
	int32_t wst;
	k_spinlock_key_t key = k_spin_lock(&lock);

	w = last;
	n = toggles;
	wst = worst;
	k_spin_unlock(&lock, key);
	if (w.n == 0u) {
		snprintf(buf, len, "P8.18: %u toggles, every %u us", n, HALF_US);
		return;
	}
	snprintf(buf, len,
		 "P8.18: %u toggles, every %u us; last %u off by %d to %d ns, mean %d; worst %d ns",
		 n, HALF_US, w.n, GTC_NS(w.min), GTC_NS(w.max), GTC_NS((int32_t)(w.sum / w.n)),
		 GTC_NS(wst));
}

static int blink_init(void)
{
	int ret;

	if (!gpio_is_ready_dt(&pin)) {
		LOG_ERR("blink: GPIO2 is not ready");
		return 0;
	}
	ret = gpio_pin_configure_dt(&pin, GPIO_OUTPUT_INACTIVE);
	if (ret) {
		LOG_ERR("blink: P8.18 configure failed (%d)", ret);
		return 0;
	}
	k_timer_start(&timer, K_USEC(HALF_US), K_USEC(HALF_US));
	LOG_INF("blink: P8.18 toggles every %u us", HALF_US);
	return 0;
}

SYS_INIT(blink_init, APPLICATION, CONFIG_APPLICATION_INIT_PRIORITY);
```

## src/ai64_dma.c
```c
/* SPDX-License-Identifier: MIT */
/*
 * R5F0_0's DMA: one memory-to-memory channel of the main NAVSS UDMA.
 *
 * Zephyr has no UDMA driver for J721E, so this file does what Linux's and
 * U-Boot's k3-udma drivers do for a memcpy channel, polled:
 *
 * - From the device manager, over TI-SCI (Zephyr's driver): this host's
 *   ranges of UDMAP transmit and receive channels and of general-purpose
 *   rings; then ring configs for the channel's transmit ring (ring n for
 *   channel n) and a completion ring, the channel pair's configs as block
 *   copy channels (TI-SCI channel type 12), and the PSI-L pairing that
 *   joins the transmit thread to the receive thread.
 * - Then, with no more TI-SCI: each copy is one CPPI5 TR descriptor with
 *   one type-15 TR (source and destination, up to 64 KiB here). The core
 *   writes its address into the transmit ring and rings the ring's
 *   doorbell; the UDMA reads the descriptor, moves the bytes, and returns
 *   the descriptor to the completion ring, which the core polls.
 * - ai64_dma_copy_bell() puts a second TR after the copy, which writes a
 *   word: a doorbell for whoever waits on the copy. Every TR has the WAIT
 *   flag, so the second only starts once the first one's writes have
 *   landed, and the word is never seen before the bytes it stands for.
 *
 * The rings and the descriptor live in the non-cacheable 4 KiB that
 * boards/ai64_ipc.dtsi leaves unused (the slot for core 0 to itself), so
 * neither side needs cache work on them.
 */

#include <zephyr/kernel.h>
#include <zephyr/device.h>
#include <zephyr/drivers/firmware/tisci/tisci.h>
#include <zephyr/sys/sys_io.h>
#include <zephyr/sys/barrier.h>
#include <zephyr/logging/log.h>
#include <errno.h>
#include <string.h>

#include "ai64_dma.h"
#include "ai64_shm.h"

LOG_MODULE_REGISTER(ai64_dma, LOG_LEVEL_INF);

/* TI-SCI device IDs (k3-j721e-main.dtsi). */
#define NAVSS_ID   199u /* main NAVSS: PSI-L pairing */
#define RINGACC_ID 211u
#define UDMAP_ID   212u

/* Resource subtypes. */
#define RA_GP_RINGS     0x01u
#define UDMAP_RX_CHAN   0x0au
#define UDMAP_TX_CHAN   0x0du

/* Realtime registers: one 4 KiB page per ring and per channel. */
#define RING_RT(n)      (0x3c000000u + (n) * 0x1000u)
#define RING_RT_DB      0x10u
#define RING_RT_OCC     0x18u
#define TCHAN_RT(n)     (0x35000000u + (n) * 0x1000u)
#define RCHAN_RT(n)     (0x34000000u + (n) * 0x1000u)
#define CHAN_RT_CTL     0x0u
#define CHAN_RT_CTL_EN  BIT(31)

/* TI-SCI values the Zephyr header leaves out (TI's ti_sci_protocol.h). */
#define RING_ALL_NO_ORDER    0x1fu
#define RING_MODE_RING       0u
#define RING_ELSIZE_8        1u
#define CH_CHAN_TYPE_VALID   BIT(2)
#define CH_FETCH_SIZE_VALID  BIT(3)
#define CH_CQ_QNUM_VALID     BIT(4)
#define CHAN_TYPE_BCOPY_PBRR 12u

/* PSI-L thread IDs of main UDMAP channel n. */
#define PSIL_SRC(n) (0x1000u + (n))
#define PSIL_DST(n) (0x9000u + (n))

#define RING_ELEMS 16u

/* CPPI5 TR descriptor: a 64-byte header record, one 64-byte TR, and its response. */
struct tr15 {
	uint32_t flags;
	uint16_t icnt0, icnt1;
	uint64_t addr;
	int32_t dim1;
	uint16_t icnt2, icnt3;
	int32_t dim2, dim3;
	uint32_t reserved;
	int32_t ddim1;
	uint64_t daddr;
	int32_t ddim2, ddim3;
	uint16_t dicnt0, dicnt1, dicnt2, dicnt3;
} __packed __aligned(64);

#define MAX_TRS 2u

struct trdesc {
	uint32_t info0, info1, info2, tag;
	uint8_t pad[48];
	struct tr15 tr[MAX_TRS];
	uint32_t response[MAX_TRS];
} __aligned(64);

BUILD_ASSERT(sizeof(struct tr15) == 64, "a type-15 TR is 64 bytes");

#define INFO0_TYPE_TR       (3u << 30)
#define INFO1_RECSIZE_64B   (2u << 24)
#define INFO1_PKTID(id)     ((uint32_t)(id) << 14)
#define INFO1_FLOWID_NONE   0x3fffu
#define TR_TYPE15           15u
#define TR_WAIT             BIT(5)
#define TR_CSF_SUPR_EVT     (BIT(2) << 24)
#define TR_CSF_EOP          (BIT(7) << 24)

/* The non-cacheable slot: descriptor, the two rings, and a doorbell's word. */
struct dma_mem {
	struct trdesc desc;
	uint64_t tx_ring[RING_ELEMS];
	uint64_t cq_ring[RING_ELEMS];
	uint32_t bell;
};

#define DMA_MEM_NODE DT_NODELABEL(ai64_dma_mem)
BUILD_ASSERT(DT_REG_SIZE(DMA_MEM_NODE) >= sizeof(struct dma_mem), "the DMA slot holds it");
static volatile struct dma_mem *const mem = (volatile struct dma_mem *)DT_REG_ADDR(DMA_MEM_NODE);

static const struct device *const dmsc = DEVICE_DT_GET(DT_NODELABEL(dmsc));
static K_MUTEX_DEFINE(lock);
static uint16_t chan, cq_ring;
static uint32_t tx_widx, cq_ridx;
static bool ready;

static int setup(void)
{
	struct tisci_msg_rm_udmap_tx_ch_cfg tx = {0};
	struct tisci_msg_rm_udmap_rx_ch_cfg rx = {0};
	uint16_t t0 = 0, tn = 0, r0 = 0, rn = 0, g0 = 0, gn = 0;
	int ret;

	ret = tisci_cmd_get_resource_range(dmsc, UDMAP_ID, UDMAP_TX_CHAN, &t0, &tn);
	ret = ret ? ret : tisci_cmd_get_resource_range(dmsc, UDMAP_ID, UDMAP_RX_CHAN, &r0, &rn);
	ret = ret ? ret : tisci_cmd_get_resource_range(dmsc, RINGACC_ID, RA_GP_RINGS, &g0, &gn);
	if (ret) {
		LOG_ERR("dma: no UDMA resources for this host (%d)", ret);
		return ret;
	}
	/* A pair needs the same number from both ranges. */
	if (r0 > t0 || r0 + rn <= t0 || tn == 0 || gn == 0) {
		LOG_ERR("dma: tx %u+%u and rx %u+%u share no channel", t0, tn, r0, rn);
		return -ENODEV;
	}
	chan = t0;
	cq_ring = g0;

	/*
	 * A pairing the last run left: undone (a NACK just means there was
	 * none). Its channel is off already (ai64_dma_stop() at shutdown).
	 * The channel's realtime registers are not touched before TI-SCI has
	 * configured it for this host: an R5F write there before that is
	 * refused, and the abort it leaves pending keeps the core out of WFI,
	 * so the kernel cannot stop it ("can't stop rproc: -110").
	 */
	(void)tisci_cmd_rm_psil_unpair(dmsc, NAVSS_ID, PSIL_SRC(chan), PSIL_DST(chan));

	memset((void *)mem, 0, sizeof(*mem));
	ret = tisci_cmd_ring_config(dmsc, RING_ALL_NO_ORDER, RINGACC_ID, chan,
				    (uint32_t)(uintptr_t)mem->tx_ring, 0, RING_ELEMS, RING_MODE_RING,
				    RING_ELSIZE_8, 0);
	ret = ret ? ret : tisci_cmd_ring_config(dmsc, RING_ALL_NO_ORDER, RINGACC_ID, cq_ring,
						(uint32_t)(uintptr_t)mem->cq_ring, 0, RING_ELEMS,
						RING_MODE_RING, RING_ELSIZE_8, 0);
	if (ret) {
		LOG_ERR("dma: ring config failed (%d)", ret);
		return ret;
	}

	tx.valid_params = CH_CHAN_TYPE_VALID | CH_FETCH_SIZE_VALID | CH_CQ_QNUM_VALID;
	tx.nav_id = UDMAP_ID;
	tx.index = chan;
	tx.tx_chan_type = CHAN_TYPE_BCOPY_PBRR;
	tx.tx_fetch_size = 16u >> 2; /* the descriptor's first 16 bytes, in words */
	tx.txcq_qnum = cq_ring;
	ret = tisci_cmd_rm_udmap_tx_ch_cfg(dmsc, &tx);
	if (ret) {
		LOG_ERR("dma: tx channel %u config failed (%d)", chan, ret);
		return ret;
	}
	rx.valid_params = CH_CHAN_TYPE_VALID | CH_FETCH_SIZE_VALID | CH_CQ_QNUM_VALID;
	rx.nav_id = UDMAP_ID;
	rx.index = chan;
	rx.rx_chan_type = CHAN_TYPE_BCOPY_PBRR;
	rx.rx_fetch_size = 16u >> 2;
	rx.rxcq_qnum = cq_ring;
	ret = tisci_cmd_rm_udmap_rx_ch_cfg(dmsc, &rx);
	if (ret) {
		LOG_ERR("dma: rx channel %u config failed (%d)", chan, ret);
		return ret;
	}
	ret = tisci_cmd_rm_psil_pair(dmsc, NAVSS_ID, PSIL_SRC(chan), PSIL_DST(chan));
	if (ret) {
		LOG_ERR("dma: PSI-L pair %#x -> %#x failed (%d)", PSIL_SRC(chan), PSIL_DST(chan), ret);
		return ret;
	}
	sys_write32(CHAN_RT_CTL_EN, RCHAN_RT(chan) + CHAN_RT_CTL);
	sys_write32(CHAN_RT_CTL_EN, TCHAN_RT(chan) + CHAN_RT_CTL);
	tx_widx = 0;
	cq_ridx = 0;
	LOG_INF("dma: UDMA channel %u, transmit ring %u, completion ring %u", chan, chan, cq_ring);
	return 0;
}

void ai64_dma_stop(void)
{
	if (!ready) {
		return;
	}
	sys_write32(0, TCHAN_RT(chan) + CHAN_RT_CTL);
	sys_write32(0, RCHAN_RT(chan) + CHAN_RT_CTL);
	ready = false;
}

static void tr_fill(volatile struct tr15 *tr, uint64_t dst, uint64_t src, uint32_t len,
		    bool last)
{
	tr->flags = TR_TYPE15 | TR_WAIT | TR_CSF_SUPR_EVT | (last ? TR_CSF_EOP : 0u);
	tr->addr = src;
	tr->icnt0 = len;
	tr->icnt1 = 1;
	tr->icnt2 = 1;
	tr->icnt3 = 1;
	tr->dim1 = len;
	tr->daddr = dst;
	tr->dicnt0 = len;
	tr->dicnt1 = 1;
	tr->dicnt2 = 1;
	tr->dicnt3 = 1;
	tr->ddim1 = len;
}

/* One descriptor: the copy, and with bell the doorbell word after it. */
static int run(uint64_t dst, uint64_t src, uint32_t len, const uint64_t *bell, uint32_t value,
	       uint32_t *ns)
{
	volatile struct trdesc *d = &mem->desc;
	uint32_t ntr = bell ? 2u : 1u;
	uint32_t t0, waited;
	uint64_t got;
	int ret = 0;

	if (len == 0 || len > 0xffffu) {
		return -EINVAL;
	}
	k_mutex_lock(&lock, K_FOREVER);
	if (!ready) {
		ret = setup();
		ready = ret == 0;
	}
	if (ret) {
		goto out;
	}

	memset((void *)d, 0, sizeof(*d));
	d->info0 = INFO0_TYPE_TR | (ntr - 1u); /* the last TR's index */
	d->info1 = INFO1_RECSIZE_64B | INFO1_PKTID(0) | INFO1_FLOWID_NONE;
	d->info2 = cq_ring; /* return ring */
	tr_fill(&d->tr[0], dst, src, len, ntr == 1u);
	if (bell) {
		mem->bell = value;
		tr_fill(&d->tr[1], *bell, (uint64_t)(uintptr_t)&mem->bell, sizeof(uint32_t), true);
	}
	barrier_dmem_fence_full();

	t0 = sys_read32(AI64_GTC_ADDR + 8u);
	mem->tx_ring[tx_widx] = (uint64_t)(uintptr_t)d;
	tx_widx = (tx_widx + 1u) % RING_ELEMS;
	barrier_dmem_fence_full();
	sys_write32(1, RING_RT(chan) + RING_RT_DB);

	/* The descriptor comes back on the completion ring. */
	while ((sys_read32(RING_RT(cq_ring) + RING_RT_OCC) & 0x1fffffu) == 0) {
		waited = sys_read32(AI64_GTC_ADDR + 8u) - t0;
		if (waited > AI64_GTC_HZ / 10u) {
			LOG_ERR("dma: no completion in 100 ms");
			ready = false;
			ret = -ETIMEDOUT;
			goto out;
		}
	}
	waited = sys_read32(AI64_GTC_ADDR + 8u) - t0;
	got = mem->cq_ring[cq_ridx];
	cq_ridx = (cq_ridx + 1u) % RING_ELEMS;
	sys_write32((uint32_t)-1, RING_RT(cq_ring) + RING_RT_DB);
	if (got != (uint64_t)(uintptr_t)d) {
		LOG_ERR("dma: completion %#llx is not the descriptor", (unsigned long long)got);
		ret = -EIO;
		goto out;
	}
	if (ns) {
		*ns = waited * (1000000000u / AI64_GTC_HZ);
	}
out:
	k_mutex_unlock(&lock);
	return ret;
}

int ai64_dma_copy(uint64_t dst, uint64_t src, uint32_t len, uint32_t *ns)
{
	return run(dst, src, len, NULL, 0, ns);
}

int ai64_dma_copy_bell(uint64_t dst, uint64_t src, uint32_t len, uint64_t bell, uint32_t value,
		       uint32_t *ns)
{
	return run(dst, src, len, &bell, value, ns);
}
```
